AUTOSAR XML (schema 4-2-2)
package /AUTOLIV/SoftwareComponents/NvmIf
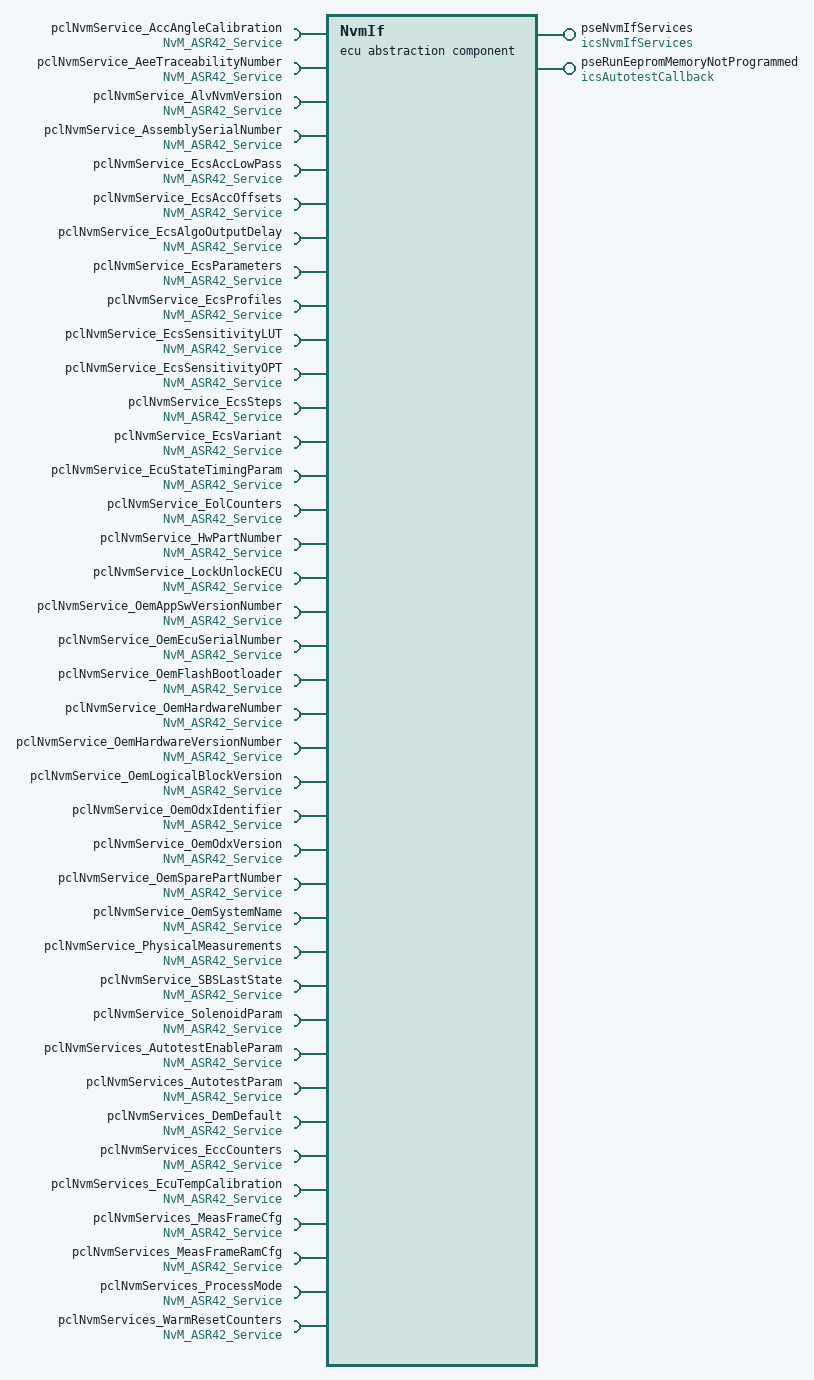
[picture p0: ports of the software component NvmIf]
  ecu abstraction sw component type NvmIf: category=BSW_Memory_Services
    39 x require port, all with required-interface=NvM_ASR42_Service:
      pclNvmService_AccAngleCalibration
        required-com-specs:
          GetErrorStatus
          SetDataIndex
          GetDataIndex
          SetRamBlockStatus
          ReadBlock
          ReadPRAMBlock
          WriteBlock
          WritePRAMBlock
          RestoreBlockDefaults
          RestorePRAMBlockDefaults
          EraseBlock
          InvalidateNvBlock
      pclNvmService_AeeTraceabilityNumber
        required-com-specs:
          GetErrorStatus
          SetDataIndex
          GetDataIndex
          SetRamBlockStatus
          ReadBlock
          ReadPRAMBlock
          WriteBlock
          WritePRAMBlock
          RestoreBlockDefaults
          RestorePRAMBlockDefaults
          EraseBlock
          InvalidateNvBlock
      pclNvmService_AlvNvmVersion
        required-com-specs:
          GetErrorStatus
          SetDataIndex
          GetDataIndex
          SetRamBlockStatus
          ReadBlock
          ReadPRAMBlock
          WriteBlock
          WritePRAMBlock
          RestoreBlockDefaults
          RestorePRAMBlockDefaults
          EraseBlock
          InvalidateNvBlock
      pclNvmService_AssemblySerialNumber
        required-com-specs:
          GetErrorStatus
          SetDataIndex
          GetDataIndex
          SetRamBlockStatus
          ReadBlock
          ReadPRAMBlock
          WriteBlock
          WritePRAMBlock
          RestoreBlockDefaults
          RestorePRAMBlockDefaults
          EraseBlock
          InvalidateNvBlock
      pclNvmService_EcsAccLowPass
        required-com-specs:
          GetErrorStatus
          SetDataIndex
          GetDataIndex
          SetRamBlockStatus
          ReadBlock
          ReadPRAMBlock
          WriteBlock
          WritePRAMBlock
          RestoreBlockDefaults
          RestorePRAMBlockDefaults
          EraseBlock
          InvalidateNvBlock
      pclNvmService_EcsAccOffsets
        required-com-specs:
          GetErrorStatus
          SetDataIndex
          GetDataIndex
          SetRamBlockStatus
          ReadBlock
          ReadPRAMBlock
          WriteBlock
          WritePRAMBlock
          RestoreBlockDefaults
          RestorePRAMBlockDefaults
          EraseBlock
          InvalidateNvBlock
      pclNvmService_EcsAlgoOutputDelay
        required-com-specs:
          GetErrorStatus
          SetDataIndex
          GetDataIndex
          SetRamBlockStatus
          ReadBlock
          ReadPRAMBlock
          WriteBlock
          WritePRAMBlock
          RestoreBlockDefaults
          RestorePRAMBlockDefaults
          EraseBlock
          InvalidateNvBlock
      pclNvmService_EcsParameters
        required-com-specs:
          GetErrorStatus
          SetDataIndex
          GetDataIndex
          SetRamBlockStatus
          ReadBlock
          ReadPRAMBlock
          WriteBlock
          WritePRAMBlock
          RestoreBlockDefaults
          RestorePRAMBlockDefaults
          EraseBlock
          InvalidateNvBlock
      pclNvmService_EcsProfiles
        required-com-specs:
          GetErrorStatus
          SetDataIndex
          GetDataIndex
          SetRamBlockStatus
          ReadBlock
          ReadPRAMBlock
          WriteBlock
          WritePRAMBlock
          RestoreBlockDefaults
          RestorePRAMBlockDefaults
          EraseBlock
          InvalidateNvBlock
      pclNvmService_EcsSensitivityLUT
        required-com-specs:
          GetErrorStatus
          SetDataIndex
          GetDataIndex
          SetRamBlockStatus
          ReadBlock
          ReadPRAMBlock
          WriteBlock
          WritePRAMBlock
          RestoreBlockDefaults
          RestorePRAMBlockDefaults
          EraseBlock
          InvalidateNvBlock
      pclNvmService_EcsSensitivityOPT
        required-com-specs:
          GetErrorStatus
          SetDataIndex
          GetDataIndex
          SetRamBlockStatus
          ReadBlock
          ReadPRAMBlock
          WriteBlock
          WritePRAMBlock
          RestoreBlockDefaults
          RestorePRAMBlockDefaults
          EraseBlock
          InvalidateNvBlock
      pclNvmService_EcsSteps
        required-com-specs:
          GetErrorStatus
          SetDataIndex
          GetDataIndex
          SetRamBlockStatus
          ReadBlock
          ReadPRAMBlock
          WriteBlock
          WritePRAMBlock
          RestoreBlockDefaults
          RestorePRAMBlockDefaults
          EraseBlock
          InvalidateNvBlock
      pclNvmService_EcsVariant
        required-com-specs:
          GetErrorStatus
          SetDataIndex
          GetDataIndex
          SetRamBlockStatus
          ReadBlock
          ReadPRAMBlock
          WriteBlock
          WritePRAMBlock
          RestoreBlockDefaults
          RestorePRAMBlockDefaults
          EraseBlock
          InvalidateNvBlock
      pclNvmService_EcuStateTimingParam
        required-com-specs:
          GetErrorStatus
          SetDataIndex
          GetDataIndex
          SetRamBlockStatus
          ReadBlock
          ReadPRAMBlock
          WriteBlock
          WritePRAMBlock
          RestoreBlockDefaults
          RestorePRAMBlockDefaults
          EraseBlock
          InvalidateNvBlock
      pclNvmService_EolCounters
        required-com-specs:
          GetErrorStatus
          SetDataIndex
          GetDataIndex
          SetRamBlockStatus
          ReadBlock
          ReadPRAMBlock
          WriteBlock
          WritePRAMBlock
          RestoreBlockDefaults
          RestorePRAMBlockDefaults
          EraseBlock
          InvalidateNvBlock
      pclNvmService_HwPartNumber
        required-com-specs:
          GetErrorStatus
          SetDataIndex
          GetDataIndex
          SetRamBlockStatus
          ReadBlock
          ReadPRAMBlock
          WriteBlock
          WritePRAMBlock
          RestoreBlockDefaults
          RestorePRAMBlockDefaults
          EraseBlock
          InvalidateNvBlock
      pclNvmService_LockUnlockECU
        required-com-specs:
          GetErrorStatus
          SetDataIndex
          GetDataIndex
          SetRamBlockStatus
          ReadBlock
          ReadPRAMBlock
          WriteBlock
          WritePRAMBlock
          RestoreBlockDefaults
          RestorePRAMBlockDefaults
          EraseBlock
          InvalidateNvBlock
      pclNvmService_OemAppSwVersionNumber
        required-com-specs:
          GetErrorStatus
          SetDataIndex
          GetDataIndex
          SetRamBlockStatus
          ReadBlock
          ReadPRAMBlock
          WriteBlock
          WritePRAMBlock
          RestoreBlockDefaults
          RestorePRAMBlockDefaults
          EraseBlock
          InvalidateNvBlock
      pclNvmService_OemEcuSerialNumber
        required-com-specs:
          GetErrorStatus
          SetDataIndex
          GetDataIndex
          SetRamBlockStatus
          ReadBlock
          ReadPRAMBlock
          WriteBlock
          WritePRAMBlock
          RestoreBlockDefaults
          RestorePRAMBlockDefaults
          EraseBlock
          InvalidateNvBlock
      pclNvmService_OemFlashBootloader
        required-com-specs:
          GetErrorStatus
          SetDataIndex
          GetDataIndex
          SetRamBlockStatus
          ReadBlock
          ReadPRAMBlock
          WriteBlock
          WritePRAMBlock
          RestoreBlockDefaults
          RestorePRAMBlockDefaults
          EraseBlock
          InvalidateNvBlock
      pclNvmService_OemHardwareNumber
        required-com-specs:
          GetErrorStatus
          SetDataIndex
          GetDataIndex
          SetRamBlockStatus
          ReadBlock
          ReadPRAMBlock
          WriteBlock
          WritePRAMBlock
          RestoreBlockDefaults
          RestorePRAMBlockDefaults
          EraseBlock
          InvalidateNvBlock
      pclNvmService_OemHardwareVersionNumber
        required-com-specs:
          GetErrorStatus
          SetDataIndex
          GetDataIndex
          SetRamBlockStatus
          ReadBlock
          ReadPRAMBlock
          WriteBlock
          WritePRAMBlock
          RestoreBlockDefaults
          RestorePRAMBlockDefaults
          EraseBlock
          InvalidateNvBlock
      pclNvmService_OemLogicalBlockVersion
        required-com-specs:
          GetErrorStatus
          SetDataIndex
          GetDataIndex
          SetRamBlockStatus
          ReadBlock
          ReadPRAMBlock
          WriteBlock
          WritePRAMBlock
          RestoreBlockDefaults
          RestorePRAMBlockDefaults
          EraseBlock
          InvalidateNvBlock
      pclNvmService_OemOdxIdentifier
        required-com-specs:
          GetErrorStatus
          SetDataIndex
          GetDataIndex
          SetRamBlockStatus
          ReadBlock
          ReadPRAMBlock
          WriteBlock
          WritePRAMBlock
          RestoreBlockDefaults
          RestorePRAMBlockDefaults
          EraseBlock
          InvalidateNvBlock
      pclNvmService_OemOdxVersion
        required-com-specs:
          GetErrorStatus
          SetDataIndex
          GetDataIndex
          SetRamBlockStatus
          ReadBlock
          ReadPRAMBlock
          WriteBlock
          WritePRAMBlock
          RestoreBlockDefaults
          RestorePRAMBlockDefaults
          EraseBlock
          InvalidateNvBlock
      pclNvmService_OemSparePartNumber
        required-com-specs:
          GetErrorStatus
          SetDataIndex
          GetDataIndex
          SetRamBlockStatus
          ReadBlock
          ReadPRAMBlock
          WriteBlock
          WritePRAMBlock
          RestoreBlockDefaults
          RestorePRAMBlockDefaults
          EraseBlock
          InvalidateNvBlock
      pclNvmService_OemSystemName
        required-com-specs:
          GetErrorStatus
          SetDataIndex
          GetDataIndex
          SetRamBlockStatus
          ReadBlock
          ReadPRAMBlock
          WriteBlock
          WritePRAMBlock
          RestoreBlockDefaults
          RestorePRAMBlockDefaults
          EraseBlock
          InvalidateNvBlock
      pclNvmService_PhysicalMeasurements
        required-com-specs:
          GetErrorStatus
          SetDataIndex
          GetDataIndex
          SetRamBlockStatus
          ReadBlock
          ReadPRAMBlock
          WriteBlock
          WritePRAMBlock
          RestoreBlockDefaults
          RestorePRAMBlockDefaults
          EraseBlock
          InvalidateNvBlock
      pclNvmService_SBSLastState
        required-com-specs:
          GetErrorStatus
          SetDataIndex
          GetDataIndex
          SetRamBlockStatus
          ReadBlock
          ReadPRAMBlock
          WriteBlock
          WritePRAMBlock
          RestoreBlockDefaults
          RestorePRAMBlockDefaults
          EraseBlock
          InvalidateNvBlock
      pclNvmService_SolenoidParam
        required-com-specs:
          GetErrorStatus
          SetDataIndex
          GetDataIndex
          SetRamBlockStatus
          ReadBlock
          ReadPRAMBlock
          WriteBlock
          WritePRAMBlock
          RestoreBlockDefaults
          RestorePRAMBlockDefaults
          EraseBlock
          InvalidateNvBlock
      pclNvmServices_AutotestEnableParam
        required-com-specs:
          GetErrorStatus
          SetDataIndex
          GetDataIndex
          SetRamBlockStatus
          ReadBlock
          ReadPRAMBlock
          WriteBlock
          WritePRAMBlock
          RestoreBlockDefaults
          RestorePRAMBlockDefaults
          EraseBlock
          InvalidateNvBlock
      pclNvmServices_AutotestParam
        required-com-specs:
          GetErrorStatus
          SetDataIndex
          GetDataIndex
          SetRamBlockStatus
          ReadBlock
          ReadPRAMBlock
          WriteBlock
          WritePRAMBlock
          RestoreBlockDefaults
          RestorePRAMBlockDefaults
          EraseBlock
          InvalidateNvBlock
      pclNvmServices_DemDefault
        required-com-specs:
          GetErrorStatus
          SetDataIndex
          GetDataIndex
          SetRamBlockStatus
          ReadBlock
          ReadPRAMBlock
          WriteBlock
          WritePRAMBlock
          RestoreBlockDefaults
          RestorePRAMBlockDefaults
          EraseBlock
          InvalidateNvBlock
      pclNvmServices_EccCounters
        required-com-specs:
          GetErrorStatus
          SetDataIndex
          GetDataIndex
          SetRamBlockStatus
          ReadBlock
          ReadPRAMBlock
          WriteBlock
          WritePRAMBlock
          RestoreBlockDefaults
          RestorePRAMBlockDefaults
          EraseBlock
          InvalidateNvBlock
      pclNvmServices_EcuTempCalibration
        required-com-specs:
          GetErrorStatus
          SetDataIndex
          GetDataIndex
          SetRamBlockStatus
          ReadBlock
          ReadPRAMBlock
          WriteBlock
          WritePRAMBlock
          RestoreBlockDefaults
          RestorePRAMBlockDefaults
          EraseBlock
          InvalidateNvBlock
      pclNvmServices_MeasFrameCfg
        required-com-specs:
          GetErrorStatus
          SetDataIndex
          GetDataIndex
          SetRamBlockStatus
          ReadBlock
          ReadPRAMBlock
          WriteBlock
          WritePRAMBlock
          RestoreBlockDefaults
          RestorePRAMBlockDefaults
          EraseBlock
          InvalidateNvBlock
      pclNvmServices_MeasFrameRamCfg
        required-com-specs:
          GetErrorStatus
          SetDataIndex
          GetDataIndex
          SetRamBlockStatus
          ReadBlock
          ReadPRAMBlock
          WriteBlock
          WritePRAMBlock
          RestoreBlockDefaults
          RestorePRAMBlockDefaults
          EraseBlock
          InvalidateNvBlock
      pclNvmServices_ProcessMode
        required-com-specs:
          EraseBlock
          GetDataIndex
          GetErrorStatus
          InvalidateNvBlock
          ReadBlock
          ReadPRAMBlock
          RestoreBlockDefaults
          RestorePRAMBlockDefaults
          SetDataIndex
          SetRamBlockStatus
          WriteBlock
          WritePRAMBlock
      pclNvmServices_WarmResetCounters
        required-com-specs:
          GetErrorStatus
          SetDataIndex
          GetDataIndex
          SetRamBlockStatus
          ReadBlock
          ReadPRAMBlock
          WriteBlock
          WritePRAMBlock
          RestoreBlockDefaults
          RestorePRAMBlockDefaults
          EraseBlock
          InvalidateNvBlock
    provide port pseNvmIfServices: provided-interface=icsNvmIfServices  # # Architecture Element ID ARCH_SW_NvmIf_pseNvmIfServices_ReadBlockByAddress # Description - The runnable will read the memory space specified in the {Start address} input parameter - The runnable will output the read memory bytes in the {Pointer to buffer} output parameter # Data Flow ## Inputs - {Start address} (of the memory from which data is to be retrieved) ## Outputs - {Pointer to buffer} # Linked Runnable - NvmIf_ReadBlockByAddress #Traceability --------------------------------------------------------------------------------------- # Architecture Element ID ARCH_SW_NvmIf_pseNvmIfServices_GetNvmBlockStatus # Description - The runnable will return the NvM block status on the {Block Status} output parameter for the selected {Block Id} input parameter # Data Flow ## Inputs - {Block Id} ## Outputs - {Block Status} # Linked Runnable - NvmIf_GetNvmBlockStatus #Traceability --------------------------------------------------------------------------------------- # Architecture Element ID ARCH_SW_NvmIf_pseNvmIfServices_WriteBlockByAddress # Description - The runnable will write the memory space specified in the {Start address} input parameter with the data from the {Pointer to buffer} input parameter # Data Flow ## Inputs - {Start address} (of the memory from which data is to be written) ## Outputs - {Pointer to buffer} # Linked Runnable - NvmIf_WriteBlockByAddress #Traceability --------------------------------------------------------------------------------------- # Architecture Element ID ARCH_SW_NvmIf_pseNvmIfServices_GetNvmBlockLength # Description - The runnable will output the block length in the {Block Length} output parameter for the selected {Block Id} # Data Flow ## Inputs - {Block Id} ## Outputs - {Block Length} # Linked Runnable - NvmIf_GetNvmBlockLength #Traceability --------------------------------------------------------------------------------------- # Architecture Element ID ARCH_SW_NvmIf_pseNvmIfServices_WriteNvmBlock # Description - The runnable will act as a wrapper for the Autosar NvM_WriteBlock interface for which it will pass the data that is to be written on the {Pointer to buffer} input parameter for the selected {Block Id} # Data Flow ## Inputs - {Block Id} - {Pointer to buffer} ## Outputs # Linked Runnable - NvmIf_WriteNvmBlock #Traceability --------------------------------------------------------------------------------------- # Architecture Element ID ARCH_SW_NvmIf_pseNvmIfServices_SetRamBlockStatus # Description - The runnable will act as a wrapper for the Autosar NvM_SetRamBlockStatus interface for which it will pass the {Block Status} from the input parameter for the selected {Block Id} # Data Flow ## Inputs - {Block Id} - {Block Status} - Can be TRUE, FALSE ## Outputs # Linked Runnable - NvmIf_SetRamBlockStatus #Traceability --------------------------------------------------------------------------------------- # Architecture Element ID ARCH_SW_NvmIf_pseNvmIfServices_RestorePRAMBlockDefaults # Description - The runnable will act as a wrapper for the Autosar NvM_RestorePRAMBlockDefaults interface for which it will specify on which {Block Id} the PRAM defaults should be restored # Data Flow ## Inputs - {Block Id} ## Outputs # Linked Runnable - NvmIf_RestorePRAMBlockDefaults #Traceability --------------------------------------------------------------------------------------- # Architecture Element ID ARCH_SW_NvmIf_pseNvmIfServices_GetRamAddressByBlockId # Description - The runnable will output the block RAM address in the {BlockRamAddress} output parameter for the selected {BlockId} # Data Flow ## Inputs - {Block Id} ## Outputs - {BlockRamAddress} # Linked Runnable - NvmIf_GetRamAddressByBlockId #Traceability
      provided-com-specs:
        operation=NvmIf_GetRamAddressByBlockId, queue-length=1
        operation=GetNvmBlockLength, queue-length=1
        operation=GetNvmBlockStatus, queue-length=1
        operation=ReadBlockByAddress, queue-length=1
        operation=RestorePRAMBlockDefaults, queue-length=1
        operation=SetRamBlockStatus, queue-length=1
        operation=WriteBlockByAddress, queue-length=1
        operation=WriteNvmBlock, queue-length=1
    provide port pseRunEepromMemoryNotProgrammed: server-com-spec{operation=AutotestCallback, queue-length=1}, provided-interface=icsAutotestCallback  # # Architecture Element ID - ARCH_SW_NvmIf_pseRunEepromMemoryNotProgrammed # Description - The auto-test shall read the {RAM copy of NvM Data} for each NvM block - The auto-test shall read the {NvM Block Status} for each NvM block - If the {RAM copy of NvM Data} is erased (0xFF) then the {Autotest Result} shall be NOK - If the {NvM Block Status} is RESTORED_FROM_ROM then the {Autotest Result} shall be NOK - If the data is not erased and the block status is OK then the {Autotest Result} shall be OK # Data Flow ## Inputs - {RAM copy of NvM Data} - {NvM Block Status} ## Outputs - {Autotest Result} - Can be one of the following values: OK, NOK, NOT DECIDED # Linked Runnable - NvmIf_Autotest_RunEepromMemoryNotProgrammed #Traceability
